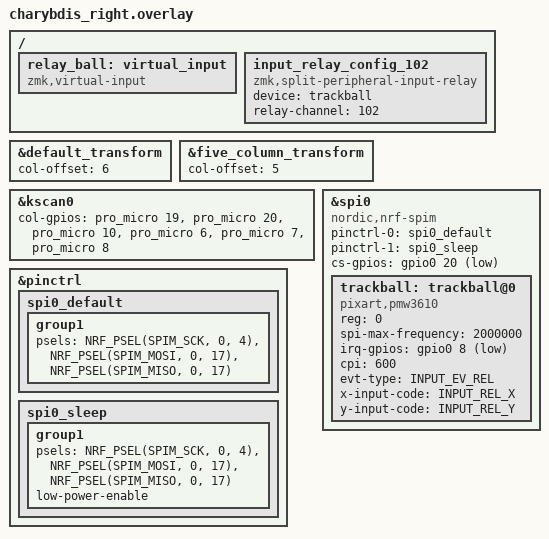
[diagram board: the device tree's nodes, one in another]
/*
 * Copyright (c) 2020 ZMK Contributors
 *
 * SPDX-License-Identifier: MIT
 */
 
#include "charybdis.dtsi"

&default_transform {
	col-offset = <6>;
};

&five_column_transform {
	col-offset = <5>;
};

&kscan0 {
	col-gpios
		= <&pro_micro 19 (GPIO_ACTIVE_HIGH | GPIO_PULL_DOWN)>
		, <&pro_micro 20 (GPIO_ACTIVE_HIGH | GPIO_PULL_DOWN)>
		, <&pro_micro 10 (GPIO_ACTIVE_HIGH | GPIO_PULL_DOWN)>
		, <&pro_micro 6 (GPIO_ACTIVE_HIGH | GPIO_PULL_DOWN)>
		, <&pro_micro 7 (GPIO_ACTIVE_HIGH | GPIO_PULL_DOWN)>
		, <&pro_micro 8 (GPIO_ACTIVE_HIGH | GPIO_PULL_DOWN)>
		;
};

&pinctrl {
    spi0_default: spi0_default {
        group1 {
            psels = <NRF_PSEL(SPIM_SCK, 0, 4)>,
                <NRF_PSEL(SPIM_MOSI, 0, 17)>,
                <NRF_PSEL(SPIM_MISO, 0, 17)>;
        };
    };

    spi0_sleep: spi0_sleep {
        group1 {
            psels = <NRF_PSEL(SPIM_SCK, 0, 4)>,
                <NRF_PSEL(SPIM_MOSI, 0, 17)>,
                <NRF_PSEL(SPIM_MISO, 0, 17)>;
            low-power-enable;
        };
    };
};

#define INPUT_EV_KEY 0x01               /**< Key event */
#define INPUT_EV_REL 0x02               /**< Relative coordinate event */
#define INPUT_EV_ABS 0x03               /**< Absolute coordinate event */
#define INPUT_EV_MSC 0x04               /**< Miscellaneous event */
#define INPUT_EV_VENDOR_START 0x30      /**< Vendor specific event start */
#define INPUT_EV_VENDOR_STOP 0x3e       /**< Vendor specific event stop */

#define INPUT_REL_X 0x00                /**< Relative X coordinate */
#define INPUT_REL_Y 0x01                /**< Relative Y coordinate */
#define INPUT_REL_WHEEL 0x08            /**< Relative wheel coordinate */
#define INPUT_REL_HWHEEL 0x06           /**< Relative horizontal wheel coordinate */
#define INPUT_REL_MISC 0x09             /**< Relative misc coordinate */

&spi0 {
    status = "okay";
    compatible = "nordic,nrf-spim";
    pinctrl-0 = <&spi0_default>;
    pinctrl-1 = <&spi0_sleep>;
    pinctrl-names = "default", "sleep";
    cs-gpios = <&gpio0 20 GPIO_ACTIVE_LOW>;

    trackball: trackball@0 {
        status = "okay";
        compatible = "pixart,pmw3610";
        reg = <0>;
        spi-max-frequency = <2000000>;
        irq-gpios = <&gpio0 8 (GPIO_ACTIVE_LOW | GPIO_PULL_UP)>;
        cpi = <600>;
        evt-type = <INPUT_EV_REL>;
        x-input-code = <INPUT_REL_X>;
        y-input-code = <INPUT_REL_Y>;
    };
};



/ {
	/* THIS make keymap binding happy only, nothing happen on peripheral side */
	relay_ball: virtual_input {
		compatible = "zmk,virtual-input";
	};

	/* for peripheral side, define (input-device)-to-(relay-channel) mapping */
	input_relay_config_102 {
		compatible = "zmk,split-peripheral-input-relay";

		/* peripheral side input device, used to... */
		/*  - be intecepted on peripheral; */
		/*  - and then, be resurrected as `zmk,virtual-device` on central; */
		device = <&trackball>;
		
		/* channel id, used to be be transfered along with all input events. */
		/* NOTE 1: pick any 8bit integer. (1 - 255) */
		/* NOTE 2: should matching relay-channel on central overlay */
		relay-channel = <102>;
	};
};
